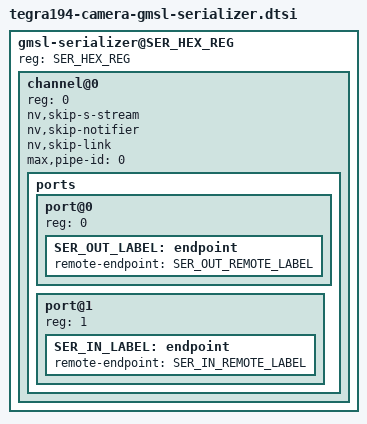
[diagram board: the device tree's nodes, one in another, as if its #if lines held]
#ifndef SER_COMPAT
#define SER_COMPAT "maxim,max96717"
#endif

#ifndef SER_HEX_REG
#define SER_HEX_REG 0x40
#endif

#ifdef SER_INDEX
#define SER_OUT_LABEL CONCAT(ser_out, SER_INDEX)
#define SER_IN_LABEL CONCAT(ser_in, SER_INDEX)
#define SER_OUT_REMOTE_LABEL CONCAT(deser_in, SER_INDEX)
#define SER_IN_REMOTE_LABEL CONCAT(ox03a_out, SER_INDEX)
#endif

#if !defined(SER_OUT_LABEL)
#error
#endif

#if !defined(SER_IN_LABEL)
#error
#endif

#if !defined(SER_OUT_REMOTE_LABEL)
#error
#endif

#if !defined(SER_IN_REMOTE_LABEL)
#error
#endif

gmsl-serializer@SER_HEX_REG {
	compatible = SER_COMPAT;
	reg = <SER_HEX_REG>;

	channel@0 {
		reg = <0>;

		nv,skip-s-stream;
		nv,skip-notifier;
		nv,skip-link;

		max,pipe-id = <0>;

		ports {
			#address-cells = <1>;
			#size-cells = <0>;

			port@0 {
				reg = <0>;

				SER_OUT_LABEL: endpoint {
					remote-endpoint = <&SER_OUT_REMOTE_LABEL>;
				};
			};

			port@1 {
				reg = <1>;

				SER_IN_LABEL: endpoint {
					remote-endpoint = <&SER_IN_REMOTE_LABEL>;
				};
			};
		};
	};
};

#undef SER_COMPAT
#undef SER_HEX_REG
#undef SER_INDEX
#undef SER_OUT_LABEL
#undef SER_IN_LABEL
#undef SER_OUT_REMOTE_LABEL
#undef SER_IN_REMOTE_LABEL
